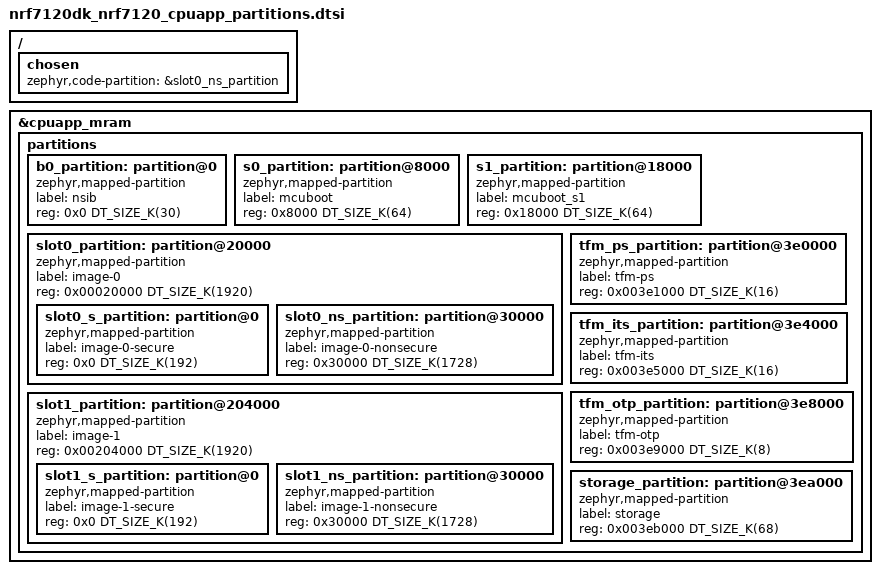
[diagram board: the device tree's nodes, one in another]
/*
 * Copyright (c) 2026 Nordic Semiconductor ASA
 *
 * SPDX-License-Identifier: LicenseRef-Nordic-5-Clause
 */

&cpuapp_mram {
	/delete-node/ partitions;
};

&cpuapp_mram {
	/*
	 * Default NVM layout on NRF7120 NS Application MCU with MCUBoot:
	 *
	 * 0x0000_0000 Boot Partition (64 KB)
	 *
	 * 0x0001_0000 Primary image area (1952 KB):
	 *   - 0x0001_0000 Secure image primary (192 KB)
	 *   - 0x0004_0000 Non-secure image primary (1760 KB)
	 *
	 * 0x001F_8000 Secondary image area (1952 KB):
	 *   - 0x001F_8000 Secure image secondary (192 KB)
	 *   - 0x0022_8000 Non-secure image secondary (1760 KB)
	 *
	 * 0x003E_0000 Protected Storage Area (16 KB)
	 * 0x003E_4000 Internal Trusted Storage Area (16 KB)
	 * 0x003E_8000 OTP / NV counters area (8 KB)
	 *
	 * 0x003E_A000 Non-secure storage, used when built with NRF_NS_STORAGE=ON,
	 *             otherwise unused (68 KB)
	 */
	partitions {
		#address-cells = <1>;
		#size-cells = <1>;
		ranges;

		b0_partition: partition@0 {
			compatible = "zephyr,mapped-partition";
			label = "nsib";
			reg = <0x0 DT_SIZE_K(30)>;
		};

		s0_partition: partition@8000 {
			compatible = "zephyr,mapped-partition";
			label = "mcuboot";
			reg = <0x8000 DT_SIZE_K(64)>;
		};

		s1_partition: partition@18000 {
			compatible = "zephyr,mapped-partition";
			label = "mcuboot_s1";
			reg = <0x18000 DT_SIZE_K(64)>;
		};

		slot0_partition: partition@20000 {
			compatible = "zephyr,mapped-partition";
			label = "image-0";
			reg = <0x00020000 DT_SIZE_K(1920)>;
			ranges = <0x0 0x00020000 DT_SIZE_K(1920)>;
			#address-cells = <1>;
			#size-cells = <1>;

			slot0_s_partition: partition@0 {
				compatible = "zephyr,mapped-partition";
				label = "image-0-secure";
				reg = <0x0 DT_SIZE_K(192)>;
			};

			slot0_ns_partition: partition@30000 {
				compatible = "zephyr,mapped-partition";
				label = "image-0-nonsecure";
				reg = <0x30000 DT_SIZE_K(1728)>;
			};
		};

		slot1_partition: partition@204000 {
			compatible = "zephyr,mapped-partition";
			label = "image-1";
			reg = <0x00204000 DT_SIZE_K(1920)>;
			ranges = <0x0 0x00204000 DT_SIZE_K(1920)>;
			#address-cells = <1>;
			#size-cells = <1>;

			slot1_s_partition: partition@0 {
				compatible = "zephyr,mapped-partition";
				label = "image-1-secure";
				reg = <0x0 DT_SIZE_K(192)>;
			};

			slot1_ns_partition: partition@30000 {
				compatible = "zephyr,mapped-partition";
				label = "image-1-nonsecure";
				reg = <0x30000 DT_SIZE_K(1728)>;
			};
		};

		tfm_ps_partition: partition@3e0000 {
			compatible = "zephyr,mapped-partition";
			label = "tfm-ps";
			reg = <0x003e1000 DT_SIZE_K(16)>;
		};

		tfm_its_partition: partition@3e4000 {
			compatible = "zephyr,mapped-partition";
			label = "tfm-its";
			reg = <0x003e5000 DT_SIZE_K(16)>;
		};

		tfm_otp_partition: partition@3e8000 {
			compatible = "zephyr,mapped-partition";
			label = "tfm-otp";
			reg = <0x003e9000 DT_SIZE_K(8)>;
		};

		storage_partition: partition@3ea000 {
			compatible = "zephyr,mapped-partition";
			label = "storage";
			reg = <0x003eb000 DT_SIZE_K(68)>;
		};
	};
};

/ {
	chosen {
		zephyr,code-partition = &slot0_ns_partition;
	};
};
